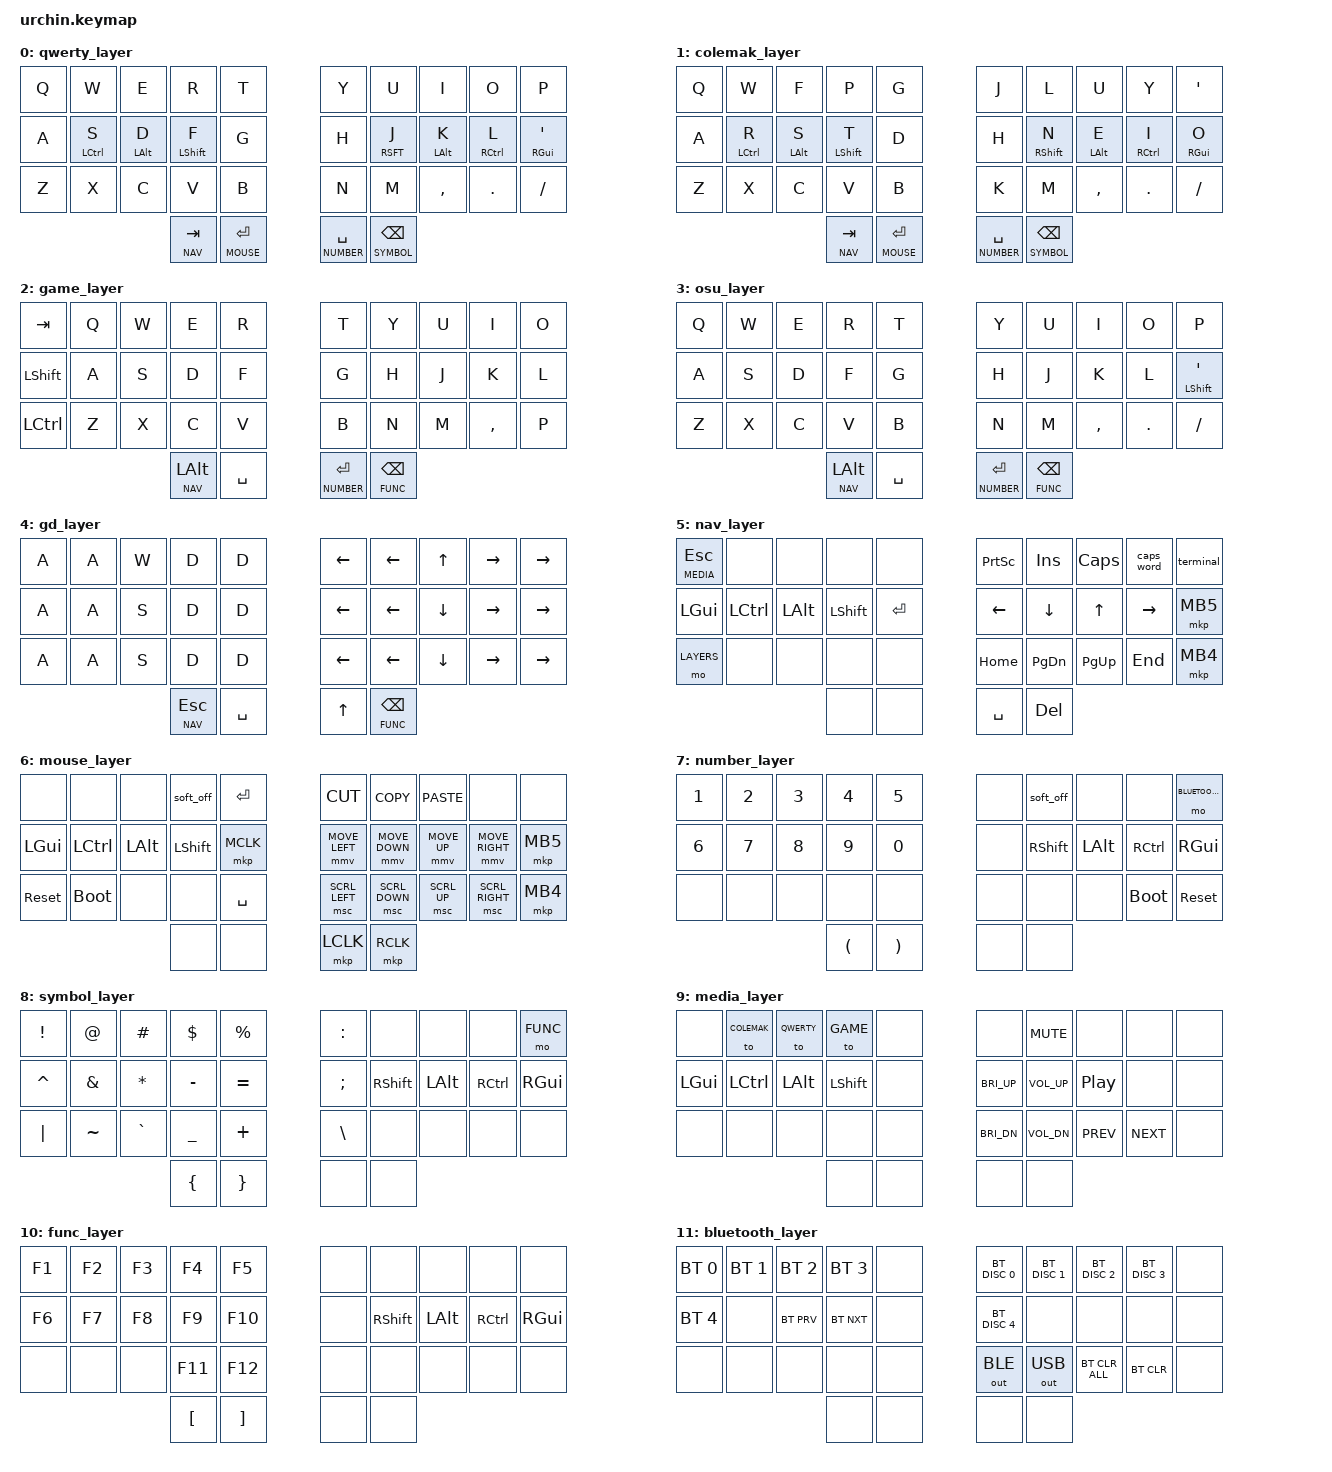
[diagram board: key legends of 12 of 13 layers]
/*
 * Copyright (c) 2020 duckyb
 *
 * SPDX-License-Identifier: MIT
 */

#include <behaviors.dtsi>
#include <dt-bindings/zmk/keys.h>
#include <dt-bindings/zmk/bt.h>
#include <dt-bindings/zmk/outputs.h>
#include "keymap_italian.h"
#include "mouse.dtsi"
#include <dt-bindings/zmk/ext_power.h>

// Layer definitions
#define QWERTY 0
#define COLEMAK 1
#define GAME 2
#define OSU 3
#define GD 4
#define NAV 5
#define MOUSE 6
#define NUMBER 7
#define SYMBOL 8
#define MEDIA 9
#define FUNC 10
#define BLUETOOTH 11
#define LAYERS 12
// -----------------

&soft_off {
    hold-time-ms = <1000>; // Only turn off it the key is held for 1 seconds or longer.
};

&sk {
	// don't release mods on other mods presses
	ignore-modifiers;
};


/ {
	behaviors {
		lpi: left_require_prior_idle {
                compatible = "zmk,behavior-hold-tap";
                #binding-cells = <2>;
                flavor = "balanced";
                tapping-term-ms = <200>;                        // <---[[produces tap if held longer than tapping-term-ms]]
                quick-tap-ms = <175>;
                require-prior-idle-ms = <60>;
                bindings = <&kp>, <&kp>;
        };

        ltp: left_tap_priority {
                compatible = "zmk,behavior-hold-tap";
                #binding-cells = <2>;
                flavor = "tap-preferred";
                tapping-term-ms = <200>;                        // <---[[produces tap if held longer than tapping-term-ms]]
                quick-tap-ms = <175>;
                require-prior-idle-ms = <60>;
                bindings = <&kp>, <&kp>;
        };

        rpi: right_require_prior_idle {
                compatible = "zmk,behavior-hold-tap";
                #binding-cells = <2>;
                flavor = "balanced";
                tapping-term-ms = <200>;                        // <---[[produces tap if held longer than tapping-term-ms]]
                quick-tap-ms = <175>;
                require-prior-idle-ms = <60>;
                bindings = <&kp>, <&kp>;
        };

        rtp: right_tap_priority {
                compatible = "zmk,behavior-hold-tap";
                #binding-cells = <2>;
                flavor = "tap-preferred";
                tapping-term-ms = <200>;                        // <---[[produces tap if held longer than tapping-term-ms]]
                quick-tap-ms = <175>;
                require-prior-idle-ms = <60>;
                bindings = <&kp>, <&kp>;
        };
	};

	macros {
		// sometimes my device thinks a modifier is being held down
		// pressing all modifiers fixes it.
		unstick: unstick {
			label = "ZM_unstick";
			compatible = "zmk,behavior-macro";
			#binding-cells = <0>;
			bindings = <&kp LSHIFT &kp RSHIFT &kp LCTRL &kp RCTRL &kp LALT &kp RALT &kp LGUI &kp RGUI>;
		};

		terminal: terminal {
            compatible = "zmk,behavior-macro";
            #binding-cells = <0>;
            bindings
                = <&macro_press &kp LCTRL>
                , <&macro_tap &kp GRAVE>
                , <&macro_release &kp LCTRL>
                ;
        };
	};

	keymap {
		compatible = "zmk,keymap";

		qwerty_layer { //0
            bindings = <
                &kp Q       &kp W           &kp E           &kp R           &kp T               &kp Y               &kp U                   &kp I           &kp O           &kp P
                &kp A       &ltp LCTRL S    &ltp LALT D     &ltp LSHFT F    &kp G               &kp H               &rtp RSFT J             &rtp LALT K     &rtp RCTRL L    &rtp RGUI QUOT
                &kp Z       &kp X           &kp C           &kp V           &kp B               &kp N               &kp M                   &kp COMMA       &kp DOT         &kp FSLH
                                                            &lt NAV TAB     &lt MOUSE ENTER     &lt NUMBER SPACE    &lt SYMBOL BACKSPACE
                >;
        };

		colemak_layer { //1
            bindings = <
                &kp Q   &kp W           &kp F           &kp P           &kp G               &kp J               &kp L                   &kp U           &kp Y           &kp QUOT
                &kp A   &ltp LCTRL R    &ltp LALT S     &ltp LSHFT T    &kp D               &kp H               &ltp RSHFT N            &ltp LALT E     &ltp RCTRL I    &rtp RGUI O
                &kp Z   &kp X           &kp C           &kp V           &kp B               &kp K               &kp M                   &kp COMMA       &kp DOT         &kp SLASH
                                                        &lt NAV TAB     &lt MOUSE ENTER     &lt NUMBER SPACE    &lt SYMBOL BACKSPACE
            >;
        };

		game_layer { //2
            bindings = <
                &kp TAB     &kp Q   &kp W   &kp E           &kp R       &kp T               &kp Y               &kp U   &kp I       &kp O
                &kp LSHFT   &kp A   &kp S   &kp D           &kp F       &kp G               &kp H               &kp J   &kp K       &kp L
                &kp LCTRL   &kp Z   &kp X   &kp C           &kp V       &kp B               &kp N               &kp M   &kp COMMA   &kp P
                                            &lt NAV LALT    &kp SPACE   &lt NUMBER ENTER    &lt FUNC BACKSPACE
                >;
        };

        osu_layer { //3
            bindings = <
                &kp Q   &kp W   &kp E   &kp R       &kp T       &kp Y               &kp U   &kp I       &kp O   &kp P
                &kp A   &kp S   &kp D   &kp F       &kp G       &kp H               &kp J   &kp K       &kp L   &rtp LSHFT QUOT
                &kp Z   &kp X   &kp C   &kp V       &kp B       &kp N               &kp M   &kp COMMA   &kp DOT &kp SLASH
                                    &lt NAV LALT    &kp SPACE   &lt NUMBER ENTER    &lt FUNC BACKSPACE
                >;
        };

        gd_layer { //4
            bindings = <
                &kp A   &kp A   &kp W   &kp D       &kp D       &kp LEFT     &kp LEFT           &kp UP     &kp RIGHT    &kp RIGHT
                &kp A   &kp A   &kp S   &kp D       &kp D       &kp LEFT     &kp LEFT           &kp DOWN   &kp RIGHT    &kp RIGHT
                &kp A   &kp A   &kp S   &kp D       &kp D       &kp LEFT     &kp LEFT           &kp DOWN   &kp RIGHT    &kp RIGHT
                                        &lt NAV ESC &kp SPACE   &kp UP    &lt FUNC BACKSPACE
                >;
        };

        nav_layer { //5
            bindings = <
                &lt MEDIA ESC   &none       &none       &none       &none       &kp PSCRN       &kp INS         &kp CAPS    &caps_word  &terminal
                &kp LGUI        &kp LCTRL   &kp LALT    &kp LSHFT   &kp ENTER   &kp LEFT        &kp DOWN        &kp UP      &kp RIGHT   &mkp MB5
                &mo LAYERS      &none       &none       &none       &none       &kp HOME        &kp PG_DN       &kp PG_UP   &kp END     &mkp MB4
                                                        &none       &none       &kp SPACE       &kp DELETE
            >;
        };

        mouse_layer { //6
            bindings = <
                &none       &none       &none       &soft_off   &kp ENTER   &kp K_CUT       &kp K_COPY      &kp K_PASTE     &none           &none
                &kp LGUI    &kp LCTRL   &kp LALT    &kp LSHFT   &mkp MCLK   &mmv MOVE_LEFT  &mmv MOVE_DOWN  &mmv MOVE_UP    &mmv MOVE_RIGHT &mkp MB5
                &sys_reset  &bootloader &none       &none       &kp SPACE   &msc SCRL_LEFT  &msc SCRL_DOWN  &msc SCRL_UP    &msc SCRL_RIGHT &mkp MB4
                                                    &none       &none       &mkp LCLK       &mkp RCLK
            >;
        };

        number_layer { //7
            bindings = <
                &kp N1      &kp N2      &kp N3      &kp N4          &kp N5          &none       &soft_off   &none       &none       &mo BLUETOOTH
                &kp N6      &kp N7      &kp N8      &kp N9          &kp N0          &none       &kp RSHFT   &kp LALT    &kp RCTRL   &kp RGUI
                &none       &none       &none       &none           &none           &none       &none       &none       &bootloader &sys_reset
                                                    &kp LPAR        &kp RPAR        &none       &none
            >;
        };

        symbol_layer { //8
            bindings = <
                &kp EXCL    &kp AT      &kp HASH    &kp DOLLAR      &kp PERCENT     &kp COLON   &none       &none       &none       &mo FUNC
                &kp CARET   &kp AMPS    &kp ASTRK   &kp MINUS       &kp EQUAL       &kp SEMI    &kp RSHFT   &kp LALT    &kp RCTRL   &kp RGUI
                &kp PIPE    &kp TILDE   &kp GRAVE   &kp UNDER       &kp PLUS        &kp BSLH    &none       &none       &none       &none
                                                    &kp LBRC        &kp RBRC        &none       &none
            >;
        };

        media_layer { //9
            bindings = <
                &none       &to COLEMAK &to QWERTY  &to GAME    &none    &none           &kp C_MUTE      &none       &none       &none
                &kp LGUI    &kp LCTRL   &kp LALT    &kp LSHFT   &none    &kp C_BRI_UP    &kp C_VOL_UP    &kp C_PP    &none       &none
                &none       &none       &none       &none       &none    &kp C_BRI_DN    &kp C_VOL_DN    &kp C_PREV  &kp C_NEXT  &none
                                                    &none       &none    &none           &none
            >;
        };

        func_layer { //10
            bindings = <
                &kp F1  &kp F2  &kp F3  &kp F4      &kp F5      &none       &none       &none       &none       &none
                &kp F6  &kp F7  &kp F8  &kp F9      &kp F10     &none       &kp RSHFT   &kp LALT    &kp RCTRL   &kp RGUI
                &none   &none   &none   &kp F11     &kp F12     &none       &none       &none       &none       &none
                                        &kp LBKT    &kp RBKT    &none       &none
            >;
        };

        bluetooth_layer { //11
            bindings = <
                &bt BT_SEL 0    &bt BT_SEL 1    &bt BT_SEL 2    &bt BT_SEL 3    &none           &bt BT_DISC 0   &bt BT_DISC 1   &bt BT_DISC 2   &bt BT_DISC 3   &none
                &bt BT_SEL 4    &none           &bt BT_PRV      &bt BT_NXT      &none           &bt BT_DISC 4   &none           &none           &none           &none
                &none           &none           &none           &none           &none           &out OUT_BLE    &out OUT_USB    &bt BT_CLR_ALL  &bt BT_CLR      &none
                                                                &none           &none           &none           &none
                >;
        };

        layers_layer { //12
            bindings = <
                &none   &none   &to OSU     &none       &none   &none   &none   &none   &none   &none
                &none   &none   &to GAME    &to QWERTY  &none   &none   &none   &none   &none   &none
                &none   &none   &to GD      &to COLEMAK &none   &none   &none   &none   &none   &none
                                            &none       &none   &none   &none
            >;
        };
	};
};

// why hello~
